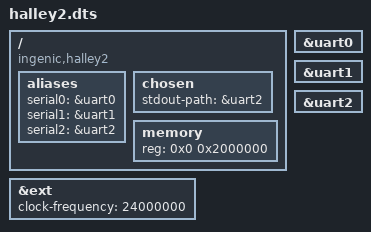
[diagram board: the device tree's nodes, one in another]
/*
 * Copyright (C) 2016 PrasannaKumar Muralidharan <prasannatsmkumar@gmail.com>
 *
 * SPDX-License-Identifier: GPL-2.0
 */

/dts-v1/;

#include "x1000.dtsi"

/ {
	compatible = "ingenic,halley2", "ingenic,x1000";

	aliases {
		serial0 = &uart0;
		serial1 = &uart1;
		serial2 = &uart2;
	};

	chosen {
		stdout-path = &uart2;
	};

	memory {
		device_type = "memory";
		reg = <0x0 0x2000000>;
	};
};

&ext {
	clock-frequency = <24000000>;
};

&uart0 {
	status = "okay";
};

&uart1 {
	status = "okay";
};

&uart2 {
	status = "okay";
};
